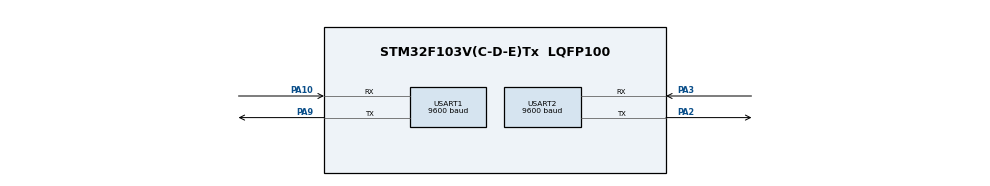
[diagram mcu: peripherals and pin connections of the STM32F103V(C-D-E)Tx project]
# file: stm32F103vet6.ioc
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Dma.Request0=USART2_RX
Dma.Request1=USART2_TX
Dma.Request2=USART1_RX
Dma.Request3=USART1_TX
Dma.USART1_RX.2.Direction=DMA_PERIPH_TO_MEMORY
Dma.USART1_RX.2.Instance=DMA1_Channel5
Dma.USART1_RX.2.MemDataAlignment=DMA_MDATAALIGN_BYTE
Dma.USART1_RX.2.MemInc=DMA_MINC_ENABLE
Dma.USART1_RX.2.Mode=DMA_NORMAL
Dma.USART1_RX.2.PeriphDataAlignment=DMA_PDATAALIGN_BYTE
Dma.USART1_RX.2.PeriphInc=DMA_PINC_DISABLE
Dma.USART1_RX.2.Priority=DMA_PRIORITY_LOW
Dma.USART1_TX.3.Direction=DMA_MEMORY_TO_PERIPH
Dma.USART1_TX.3.Instance=DMA1_Channel4
Dma.USART1_TX.3.MemDataAlignment=DMA_MDATAALIGN_BYTE
Dma.USART1_TX.3.MemInc=DMA_MINC_ENABLE
Dma.USART1_TX.3.Mode=DMA_NORMAL
Dma.USART1_TX.3.PeriphDataAlignment=DMA_PDATAALIGN_BYTE
Dma.USART1_TX.3.PeriphInc=DMA_PINC_DISABLE
Dma.USART1_TX.3.Priority=DMA_PRIORITY_LOW
Dma.USART2_RX.0.Direction=DMA_PERIPH_TO_MEMORY
Dma.USART2_RX.0.Instance=DMA1_Channel6
Dma.USART2_RX.0.MemDataAlignment=DMA_MDATAALIGN_BYTE
Dma.USART2_RX.0.MemInc=DMA_MINC_ENABLE
Dma.USART2_RX.0.Mode=DMA_NORMAL
Dma.USART2_RX.0.PeriphDataAlignment=DMA_PDATAALIGN_BYTE
Dma.USART2_RX.0.PeriphInc=DMA_PINC_DISABLE
Dma.USART2_RX.0.Priority=DMA_PRIORITY_LOW
Dma.USART2_TX.1.Direction=DMA_MEMORY_TO_PERIPH
Dma.USART2_TX.1.Instance=DMA1_Channel7
Dma.USART2_TX.1.MemDataAlignment=DMA_MDATAALIGN_BYTE
Dma.USART2_TX.1.MemInc=DMA_MINC_ENABLE
Dma.USART2_TX.1.Mode=DMA_NORMAL
Dma.USART2_TX.1.PeriphDataAlignment=DMA_PDATAALIGN_BYTE
Dma.USART2_TX.1.PeriphInc=DMA_PINC_DISABLE
Dma.USART2_TX.1.Priority=DMA_PRIORITY_LOW
Mcu.Family=STM32F1
Mcu.Name=STM32F103V(C-D-E)Tx
Mcu.Package=LQFP100
NVIC.DMA1_Channel4_IRQn=true\:0\:0\:false\:false\:true\:false\:true
NVIC.DMA1_Channel5_IRQn=true\:0\:0\:false\:false\:true\:false\:true
NVIC.DMA1_Channel6_IRQn=true\:0\:0\:false\:false\:true\:false\:true
NVIC.DMA1_Channel7_IRQn=true\:0\:0\:false\:false\:true\:false\:true
NVIC.PriorityGroup=NVIC_PRIORITYGROUP_4
NVIC.USART1_IRQn=true\:0\:0\:false\:false\:true\:true\:true
NVIC.USART2_IRQn=true\:0\:0\:false\:false\:true\:true\:true
PA10.Mode=Asynchronous
PA10.Signal=USART1_RX
PA13.Mode=Serial_Wire
PA13.Signal=SYS_JTMS-SWDIO
PA14.Mode=Serial_Wire
PA14.Signal=SYS_JTCK-SWCLK
PA2.Mode=Asynchronous
PA2.Signal=USART2_TX
PA3.Mode=Asynchronous
PA3.Signal=USART2_RX
PA9.Mode=Asynchronous
PA9.Signal=USART1_TX
ProjectManager.HeapSize=0x200
ProjectManager.StackSize=0x400
ProjectManager.TargetToolchain=MDK-ARM V5
RCC.APB1Freq_Value=8000000
RCC.APB2Freq_Value=8000000
USART1.BaudRate=9600
USART1.VirtualMode=VM_ASYNC
USART2.BaudRate=9600
USART2.VirtualMode=VM_ASYNC
board=custom

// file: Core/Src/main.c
/* USER CODE BEGIN Header */
/**
  ******************************************************************************
  * @file           : main.c
  * @brief          : Main program body
  ******************************************************************************
  * @attention
  *
  * Copyright (c) 2023 STMicroelectronics.
  * All rights reserved.
  *
  * This software is licensed under terms that can be found in the LICENSE file
  * in the root directory of this software component.
  * If no LICENSE file comes with this software, it is provided AS-IS.
  *
  ******************************************************************************
  */
/* USER CODE END Header */
#include "main.h"
#include "dma.h"
#include "usart.h"
#include "gpio.h"

/* USER CODE BEGIN PV */
uint8_t tx_buffer[10];

uint8_t  rx1_data  = 0;
uint16_t rx1_count = 0;
uint8_t  rx1_buffer[16];
uint16_t rx1_timeout = 0;
/* USER CODE END PV */

void SystemClock_Config(void);

/* USER CODE BEGIN 0 */
void HAL_UART_RxCpltCallback(UART_HandleTypeDef *huart)
{
  /* Prevent unused argument(s) compilation warning */
  UNUSED(huart);
  /* NOTE: This function should not be modified, when the callback is needed,
           the HAL_UART_RxCpltCallback could be implemented in the user file
   */
	if(huart ==&huart1){
		rx1_buffer[rx1_count++] = rx1_data;

		// over buffer size
		if(rx1_count>=sizeof(rx1_buffer)){
			// replace the last one
			rx1_count = sizeof(rx1_buffer)-1;
		}
		// get per data time ++
		rx1_timeout =1;
		HAL_UART_Receive_IT(&huart1,&rx1_data,1);

	}
}
/* USER CODE END 0 */

int main(void)
{

  /* MCU Configuration--------------------------------------------------------*/

  /* Reset of all peripherals, Initializes the Flash interface and the Systick. */
  HAL_Init();

  /* Configure the system clock */
  SystemClock_Config();

  /* Initialize all configured peripherals */
  MX_GPIO_Init();
  MX_DMA_Init();
  MX_USART2_UART_Init();
  MX_USART1_UART_Init();
  /* USER CODE BEGIN 2 */
	HAL_UART_Receive_IT(&huart1,&rx1_data,1);

  /* USER CODE END 2 */

  /* Infinite loop */
  while (1)
  {
		if(rx1_timeout >0){
			if(++rx1_timeout >= 3){
				rx1_timeout = 0;
				HAL_UART_Transmit_IT(&huart1,rx1_buffer,rx1_count);
				rx1_count = 0;
			}
		}
		HAL_Delay(1);
  }
}

void SystemClock_Config(void)
{
  RCC_OscInitTypeDef RCC_OscInitStruct = {0};
  RCC_ClkInitTypeDef RCC_ClkInitStruct = {0};

  /** Initializes the RCC Oscillators according to the specified parameters
  * in the RCC_OscInitTypeDef structure.
  */
  RCC_OscInitStruct.OscillatorType = RCC_OSCILLATORTYPE_HSI;
  RCC_OscInitStruct.HSIState = RCC_HSI_ON;
  RCC_OscInitStruct.HSICalibrationValue = RCC_HSICALIBRATION_DEFAULT;
  RCC_OscInitStruct.PLL.PLLState = RCC_PLL_NONE;
  if (HAL_RCC_OscConfig(&RCC_OscInitStruct) != HAL_OK)
  {
    Error_Handler();
  }
  /** Initializes the CPU, AHB and APB buses clocks
  */
  RCC_ClkInitStruct.ClockType = RCC_CLOCKTYPE_HCLK|RCC_CLOCKTYPE_SYSCLK
                              |RCC_CLOCKTYPE_PCLK1|RCC_CLOCKTYPE_PCLK2;
  RCC_ClkInitStruct.SYSCLKSource = RCC_SYSCLKSOURCE_HSI;
  RCC_ClkInitStruct.AHBCLKDivider = RCC_SYSCLK_DIV1;
  RCC_ClkInitStruct.APB1CLKDivider = RCC_HCLK_DIV1;
  RCC_ClkInitStruct.APB2CLKDivider = RCC_HCLK_DIV1;

  if (HAL_RCC_ClockConfig(&RCC_ClkInitStruct, FLASH_LATENCY_0) != HAL_OK)
  {
    Error_Handler();
  }
}

void Error_Handler(void)
{
  __disable_irq();
  while (1)
  {
  }
}
